VERSION ""

NS_ :

BS_:

BU_: XXX

BO_ 85 CID_SHPRSN: 8 XXX
 SG_ sig_mstjnl : 40|1@1+ (1,0) [0|1] "" XXX
 SG_ sig_nvbqlo : 56|8@1+ (1,0) [0|255] "" XXX

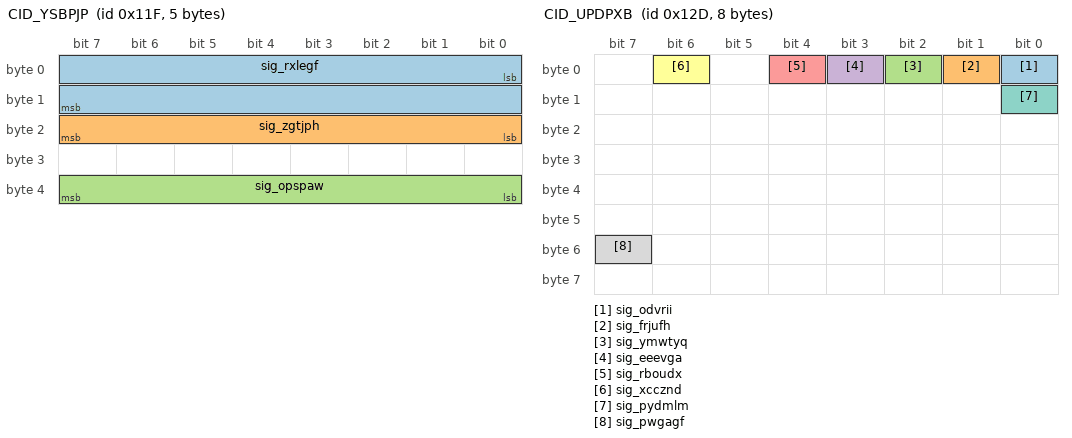
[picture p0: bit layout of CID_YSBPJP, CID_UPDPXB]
BO_ 287 CID_YSBPJP: 5 XXX
 SG_ sig_rxlegf : 0|16@1- (0.1,0) [-450|450] "" XXX
 SG_ sig_zgtjph : 16|8@1+ (4,0) [0|1020] "" XXX
 SG_ sig_opspaw : 32|8@1+ (1,0) [0|255] "" XXX

BO_ 289 CID_MHUZFI: 8 XXX
 SG_ sig_wpzvav : 0|12@1+ (1,0) [0|255] "" XXX

BO_ 301 CID_UPDPXB: 8 XXX
 SG_ sig_odvrii : 0|1@0+ (1,0) [0|1] "" XXX
 SG_ sig_frjufh : 1|1@0+ (1,0) [0|1] "" XXX
 SG_ sig_ymwtyq : 2|1@0+ (1,0) [0|1] "" XXX
 SG_ sig_eeevga : 3|1@0+ (1,0) [0|1] "" XXX
 SG_ sig_rboudx : 4|1@0+ (1,0) [0|1] "" XXX
 SG_ sig_xccznd : 6|1@0+ (1,0) [0|1] "" XXX
 SG_ sig_pydmlm : 8|1@0+ (1,0) [0|1] "" XXX
 SG_ sig_pwgagf : 55|1@0+ (1,0) [0|1] "" XXX

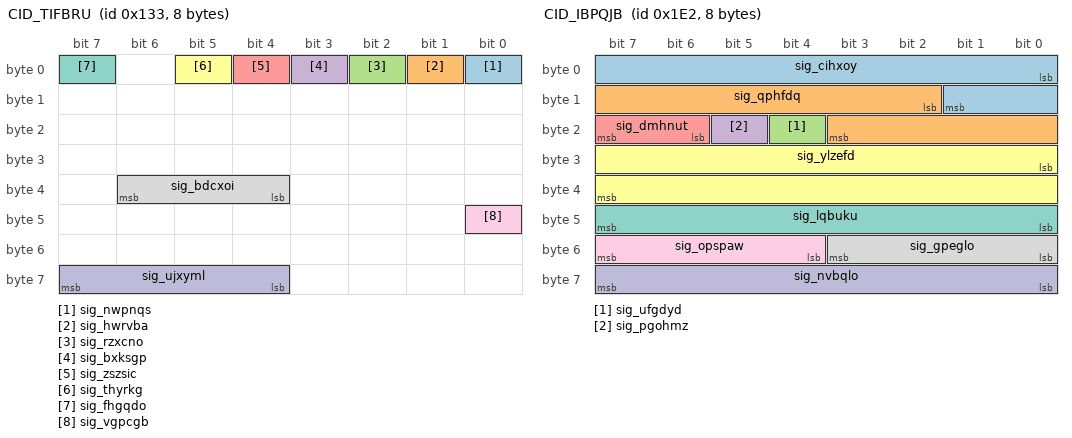
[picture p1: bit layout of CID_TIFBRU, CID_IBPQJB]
BO_ 307 CID_TIFBRU: 8 XXX
 SG_ sig_nwpnqs : 0|1@0+ (1,0) [0|1] "" XXX
 SG_ sig_hwrvba : 1|1@1+ (1,0) [0|1] "" XXX
 SG_ sig_rzxcno : 2|1@1+ (1,0) [0|1] "" XXX
 SG_ sig_bxksgp : 3|1@1+ (1,0) [0|1] "" XXX
 SG_ sig_zszsic : 4|1@0+ (1,0) [0|1] "" XXX
 SG_ sig_thyrkg : 5|1@0+ (1,0) [0|1] "" XXX
 SG_ sig_fhgqdo : 7|1@0+ (1,0) [0|1] "" XXX
 SG_ sig_bdcxoi : 36|3@1+ (1,0) [0|7] "" XXX
 SG_ sig_vgpcgb : 40|1@0+ (1,0) [0|1] "" XXX
 SG_ sig_ujxyml : 63|4@0+ (1,0) [0|15] "" XXX

BO_ 482 CID_IBPQJB: 8 XXX
 SG_ sig_cihxoy : 0|10@1- (0.01,0) [0|5] "" XXX
 SG_ sig_qphfdq : 10|10@1- (0.01,0) [-5|0] "" XXX
 SG_ sig_ufgdyd : 20|1@0+ (1,0) [0|1] "" XXX
 SG_ sig_pgohmz : 21|1@0+ (1,0) [0|1] "" XXX
 SG_ sig_dmhnut : 22|2@1+ (1,0) [0|1] "" XXX
 SG_ sig_ylzefd : 24|16@1- (0.1,0) [-780|779.9] "" XXX
 SG_ sig_lqbuku : 47|8@0+ (1,0) [0|255] "" XXX
 SG_ sig_gpeglo : 48|4@1+ (1,0) [0|15] "" XXX
 SG_ sig_opspaw : 52|4@1+ (1,0) [0|15] "" XXX
 SG_ sig_nvbqlo : 56|8@1+ (1,0) [0|255] "" XXX

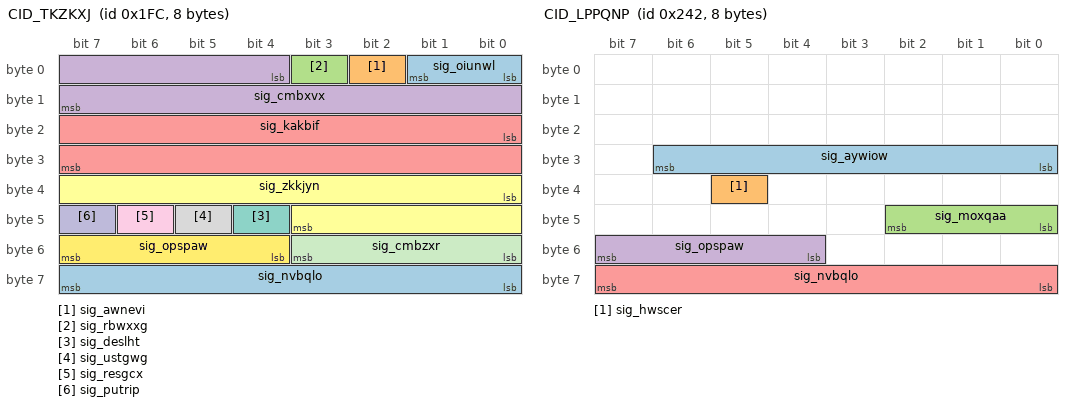
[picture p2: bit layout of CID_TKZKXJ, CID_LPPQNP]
BO_ 508 CID_TKZKXJ: 8 XXX
 SG_ sig_oiunwl : 0|2@1+ (1,0) [0|1] "" XXX
 SG_ sig_awnevi : 2|1@1+ (1,0) [0|1] "" XXX
 SG_ sig_rbwxxg : 3|1@0+ (1,0) [0|1] "" XXX
 SG_ sig_cmbxvx : 4|12@1- (1,0) [-2048|2047] "" XXX
 SG_ sig_kakbif : 16|16@1- (0.1,0) [-780|779.9] "Deg" XXX
 SG_ sig_zkkjyn : 32|12@1- (0.01,0) [0|63] "" XXX
 SG_ sig_deslht : 44|1@0+ (1,0) [0|1] "" XXX
 SG_ sig_ustgwg : 45|1@1+ (1,0) [0|255] "" XXX
 SG_ sig_resgcx : 46|1@1+ (1,0) [0|1] "" XXX
 SG_ sig_putrip : 47|1@0+ (1,0) [0|3] "" XXX
 SG_ sig_cmbzxr : 48|4@1+ (1,0) [0|15] "" XXX
 SG_ sig_opspaw : 52|4@1+ (1,0) [0|15] "" XXX
 SG_ sig_nvbqlo : 56|8@1+ (1,0) [0|255] "" XXX

BO_ 578 CID_LPPQNP: 8 XXX
 SG_ sig_aywiow : 30|7@0+ (1,0) [0|127] "" XXX
 SG_ sig_hwscer : 37|1@0+ (1,0) [0|1] "" XXX
 SG_ sig_moxqaa : 40|3@1+ (1,0) [0|7] "" XXX
 SG_ sig_opspaw : 55|4@0+ (1,0) [0|15] "" XXX
 SG_ sig_nvbqlo : 56|8@1+ (1,0) [0|255] "" XXX

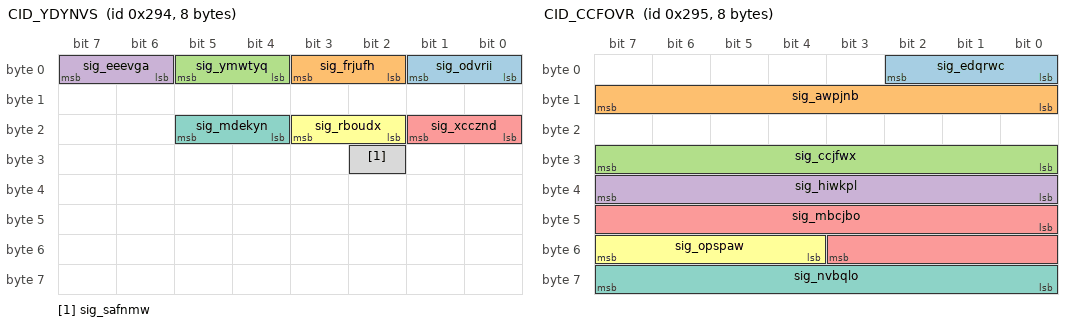
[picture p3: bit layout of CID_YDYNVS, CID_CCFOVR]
BO_ 660 CID_YDYNVS: 8 XXX
 SG_ sig_odvrii : 1|2@0+ (1,0) [0|3] "" XXX
 SG_ sig_frjufh : 3|2@0+ (1,0) [0|3] "" XXX
 SG_ sig_ymwtyq : 5|2@0+ (1,0) [0|3] "" XXX
 SG_ sig_eeevga : 7|2@0+ (1,0) [0|3] "" XXX
 SG_ sig_xccznd : 17|2@0+ (1,0) [0|3] "" XXX
 SG_ sig_rboudx : 19|2@0+ (1,0) [0|3] "" XXX
 SG_ sig_mdekyn : 21|2@0+ (1,0) [0|3] "" XXX
 SG_ sig_safnmw : 26|1@0+ (1,0) [0|1] "" XXX

BO_ 661 CID_CCFOVR: 8 XXX
 SG_ sig_edqrwc : 2|3@0+ (1,0) [0|7] "" XXX
 SG_ sig_awpjnb : 15|8@0+ (1,0) [0|255] "" XXX
 SG_ sig_ccjfwx : 31|8@0+ (1,0) [0|255] "" XXX
 SG_ sig_hiwkpl : 32|8@1+ (1,0) [0|255] "" XXX
 SG_ sig_mbcjbo : 40|12@1+ (1,0) [0|255] "" XXX
 SG_ sig_opspaw : 52|4@1+ (1,0) [0|15] "" XXX
 SG_ sig_nvbqlo : 63|8@0+ (1,0) [0|255] "" XXX

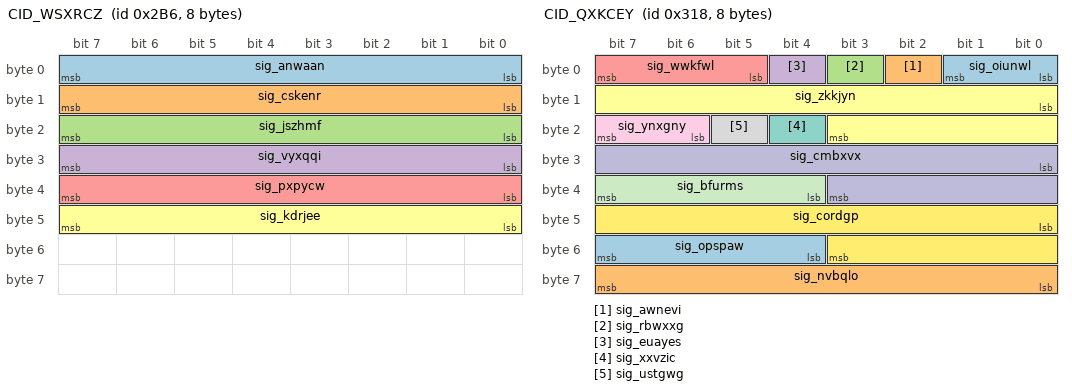
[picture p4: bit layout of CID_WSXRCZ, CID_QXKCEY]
BO_ 694 CID_WSXRCZ: 8 XXX
 SG_ sig_anwaan : 7|8@0+ (1,0) [0|255] "" XXX
 SG_ sig_cskenr : 15|8@0+ (1,0) [0|255] "" XXX
 SG_ sig_jszhmf : 23|8@0+ (1,0) [0|255] "" XXX
 SG_ sig_vyxqqi : 31|8@0+ (1,0) [0|255] "" XXX
 SG_ sig_pxpycw : 39|8@0+ (1,0) [0|255] "" XXX
 SG_ sig_kdrjee : 47|8@0+ (1,0) [0|255] "" XXX

BO_ 790 CID_KSSZPX: 8 XXX
 SG_ sig_ufqdkf : 3|4@0+ (1,0) [0|1] "" XXX
 SG_ sig_ealdik : 4|2@1+ (1,0) [0|3] "" XXX
 SG_ sig_iaiijy : 6|2@1+ (1,0) [0|3] "" XXX
 SG_ sig_beswdz : 8|2@1+ (1,0) [0|3] "" XXX
 SG_ sig_vrbsno : 10|1@1+ (1,0) [0|1] "" XXX
 SG_ sig_sihiqy : 11|4@1+ (1,0) [0|1] "" XXX
 SG_ sig_nokjrt : 15|1@0+ (1,0) [0|1] "" XXX
 SG_ sig_ylzefd : 16|11@1- (1,0) [-1024|1023] "" XXX
 SG_ sig_ufgdyd : 27|1@1+ (1,0) [0|1] "" XXX
 SG_ sig_pgohmz : 28|1@1+ (1,0) [0|3] "" XXX
 SG_ sig_wnoeiz : 29|1@0+ (1,0) [0|1] "" XXX
 SG_ sig_vikvqq : 30|1@0+ (1,0) [0|1] "" XXX
 SG_ sig_ddafoj : 31|1@0+ (1,0) [0|1] "" XXX
 SG_ sig_oxvdeb : 32|2@1+ (1,0) [0|3] "" XXX
 SG_ sig_cnyppa : 34|2@1+ (1,0) [0|3] "" XXX
 SG_ sig_ljmqjj : 36|4@1+ (1,0) [0|3] "" XXX
 SG_ sig_fbznym : 40|8@1+ (5,-5) [-5|1270] "" XXX
 SG_ sig_jzpfef : 49|2@0+ (1,0) [0|3] "" XXX
 SG_ sig_cqhiyo : 51|2@0+ (1,0) [0|3] "" XXX
 SG_ sig_opspaw : 52|4@1+ (1,0) [0|15] "" XXX
 SG_ sig_nvbqlo : 56|8@1+ (1,0) [0|15] "" XXX

BO_ 792 CID_QXKCEY: 8 XXX
 SG_ sig_oiunwl : 0|2@1+ (1,0) [0|1] "" XXX
 SG_ sig_awnevi : 2|1@1+ (1,0) [0|1] "" XXX
 SG_ sig_rbwxxg : 3|1@1+ (1,0) [0|1] "" XXX
 SG_ sig_euayes : 4|1@1+ (1,0) [0|1] "" XXX
 SG_ sig_wwkfwl : 5|3@1+ (1,0) [0|1] "" XXX
 SG_ sig_zkkjyn : 8|12@1- (1,0) [-2048|2047] "" XXX
 SG_ sig_xxvzic : 20|1@1+ (1,0) [0|1] "" XXX
 SG_ sig_ustgwg : 21|1@1+ (1,0) [0|1] "" XXX
 SG_ sig_ynxgny : 22|2@1+ (1,0) [0|15] "" XXX
 SG_ sig_cmbxvx : 24|12@1- (1,0) [-2048|2047] "" XXX
 SG_ sig_bfurms : 36|4@1+ (1,0) [0|15] "" XXX
 SG_ sig_cordgp : 40|12@1+ (1,0) [0|4095] "" XXX
 SG_ sig_opspaw : 52|4@1+ (1,0) [0|15] "" XXX
 SG_ sig_nvbqlo : 56|8@1+ (1,0) [0|255] "" XXX

BO_ 813 CID_FPKZLG: 8 XXX
 SG_ sig_zvgikm : 0|9@1+ (0.5,0) [0|255.5] "" XXX
 SG_ sig_crgucz : 9|1@1+ (1,0) [0|1] "" XXX
 SG_ sig_lhgjap : 10|3@1+ (1,0) [0|7] "" XXX
 SG_ sig_jkobrm : 13|3@1+ (1,0) [0|7] "" XXX
 SG_ sig_efmxob : 16|1@1+ (1,0) [0|1] "" XXX
 SG_ sig_dqgvyd : 17|1@1+ (1,0) [0|1] "" XXX
 SG_ sig_rbwxxg : 18|1@1+ (1,0) [0|1] "" XXX
 SG_ sig_eudesy : 19|3@1+ (1,0) [0|1] "" XXX
 SG_ sig_dmtguj : 22|1@0+ (1,0) [0|1] "" XXX
 SG_ sig_fpggzb : 23|1@0+ (1,0) [0|1] "" XXX
 SG_ sig_beswdz : 24|1@1+ (1,0) [0|1] "" XXX
 SG_ sig_teslqp : 25|7@1+ (1,0) [0|127] "" XXX
 SG_ sig_gxwmml : 32|4@1+ (1,0) [0|15] "" XXX
 SG_ sig_zkavbg : 36|12@1+ (1,0) [0|4095] "" XXX
 SG_ sig_opspaw : 48|4@1+ (1,0) [0|15] "" XXX
 SG_ sig_dseuan : 55|4@0+ (1,0) [0|15] "" XXX
 SG_ sig_nvbqlo : 56|8@1+ (1,0) [0|255] "" XXX

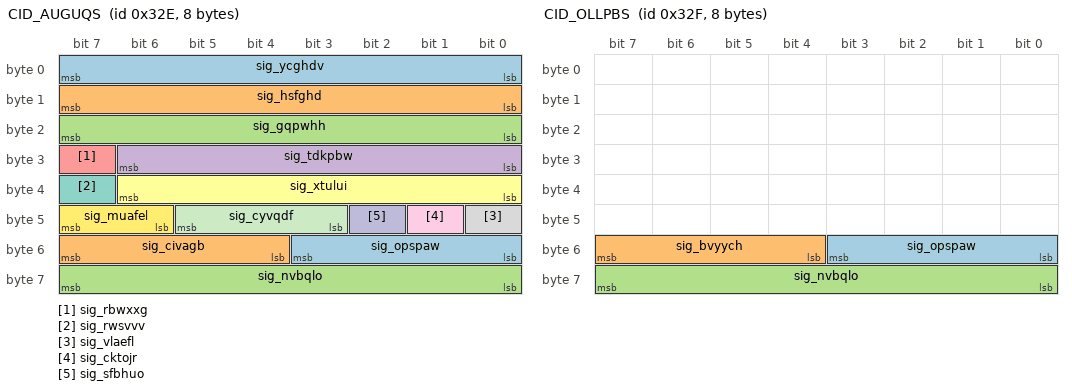
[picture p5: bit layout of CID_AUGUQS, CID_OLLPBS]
BO_ 814 CID_AUGUQS: 8 XXX
 SG_ sig_ycghdv : 0|8@1+ (0.05,-5) [-100|155] "" XXX
 SG_ sig_hsfghd : 8|8@1+ (0.05,-5) [0|1.26] "" XXX
 SG_ sig_gqpwhh : 16|8@1+ (0.05,-5) [0|1.26] "" XXX
 SG_ sig_tdkpbw : 24|7@1+ (0.2,0) [0|12.7] "" XXX
 SG_ sig_rbwxxg : 31|1@0+ (1,0) [0|1] "" XXX
 SG_ sig_xtului : 32|7@1+ (0.2,-16) [0|12.7] "" XXX
 SG_ sig_rwsvvv : 39|1@0+ (1,0) [0|1] "" XXX
 SG_ sig_vlaefl : 40|1@0+ (1,0) [0|1] "" XXX
 SG_ sig_cktojr : 41|1@0+ (1,0) [0|1] "" XXX
 SG_ sig_sfbhuo : 42|1@1+ (1,0) [0|3] "" XXX
 SG_ sig_cyvqdf : 45|3@0+ (1,0) [0|1] "" XXX
 SG_ sig_muafel : 46|2@1+ (1,0) [0|3] "" XXX
 SG_ sig_opspaw : 48|4@1+ (1,0) [0|15] "" XXX
 SG_ sig_civagb : 55|4@0+ (1,0) [0|15] "" XXX
 SG_ sig_nvbqlo : 56|8@1+ (1,0) [0|255] "" XXX

BO_ 815 CID_OLLPBS: 8 XXX
 SG_ sig_opspaw : 48|4@1+ (1,0) [0|15] "" XXX
 SG_ sig_bvyych : 55|4@0+ (1,0) [0|15] "" XXX
 SG_ sig_nvbqlo : 56|8@1+ (1,0) [0|255] "" XXX

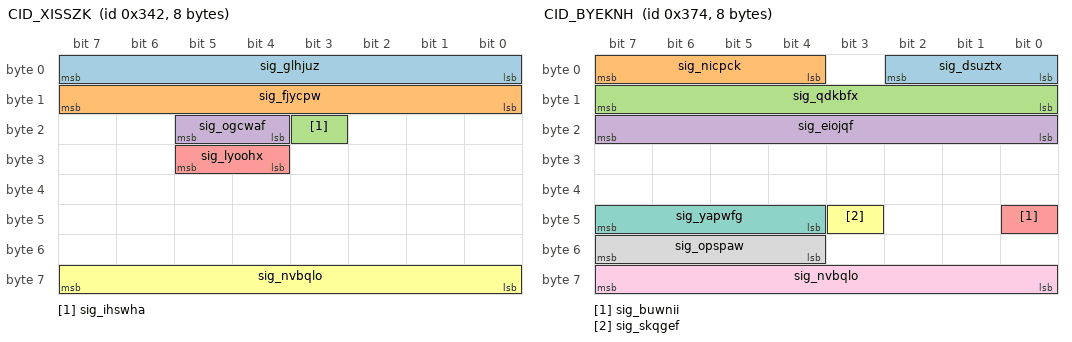
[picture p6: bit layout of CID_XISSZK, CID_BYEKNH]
BO_ 834 CID_XISSZK: 8 XXX
 SG_ sig_glhjuz : 0|8@1+ (0.01,0) [0|2.55] "" XXX
 SG_ sig_fjycpw : 8|8@1+ (0.01,0) [0|2.55] "" XXX
 SG_ sig_ihswha : 19|1@1+ (1,0) [0|1] "" XXX
 SG_ sig_ogcwaf : 20|2@1+ (1,0) [0|255] "" XXX
 SG_ sig_lyoohx : 28|2@1+ (1,0) [0|1] "" XXX
 SG_ sig_nvbqlo : 56|8@1+ (1,0) [0|255] "" XXX

 BO_ 884 CID_BYEKNH: 8 MRR
 SG_ sig_dsuztx : 2|3@0+ (1,0) [0|3] "" MRR
 SG_ sig_nicpck : 7|4@0+ (1,0) [0|15] "" MRR
 SG_ sig_qdkbfx : 15|8@0+ (0.1,-12) [0|255] "" MRR
 SG_ sig_eiojqf : 23|8@0+ (1,-100) [0|255] "" MRR
 SG_ sig_buwnii : 40|1@0+ (1,0) [0|3] "" MRR
 SG_ sig_skqgef : 43|1@0+ (1,0) [0|1] "" XXX
 SG_ sig_yapwfg : 44|4@1+ (1,0) [0|15] "" XXX
 SG_ sig_opspaw : 52|4@1+ (1,0) [0|15] "" MRR
 SG_ sig_nvbqlo : 56|8@1+ (1,0) [0|255] "" MRR

BO_ 944 CID_NYYFKY: 8 XXX
 SG_ sig_xgpfiw : 1|2@0+ (1,0) [0|3] "" XXX
 SG_ sig_drlsvk : 2|1@0+ (1,0) [0|1] "" XXX
 SG_ sig_dmlqjp : 4|2@0+ (1,0) [0|3] "" XXX
 SG_ sig_mvbupz : 5|1@0+ (1,0) [0|1] "" XXX
 SG_ sig_zjkcdw : 6|1@0+ (1,0) [0|1] "" XXX
 SG_ sig_hjdzse : 7|1@0+ (1,0) [0|1] "" XXX
 SG_ sig_drenga : 8|1@0+ (1,0) [0|1] "" XXX
 SG_ sig_fucela : 11|3@0+ (1,0) [0|7] "" XXX
 SG_ sig_rhzrzx : 12|1@0+ (1,0) [0|1] "" XXX
 SG_ sig_imwzat : 14|2@0+ (1,0) [0|3] "" XXX
 SG_ sig_edcaux : 15|1@0+ (1,0) [0|1] "" XXX
 SG_ sig_kfzssy : 16|1@0+ (1,0) [0|1] "" XXX
 SG_ sig_yicpfo : 18|2@0+ (1,0) [0|3] "" XXX
 SG_ sig_aohsrd : 19|1@0+ (1,0) [0|1] "" XXX
 SG_ sig_vztlec : 23|4@0+ (1,0) [0|15] "" XXX
 SG_ sig_euzxdb : 24|28@1+ (1,0) [0|268435455] "" XXX
 SG_ sig_opspaw : 52|4@1+ (1,0) [0|15] "" XXX
 SG_ sig_nvbqlo : 56|8@1+ (1,0) [0|255] "" XXX

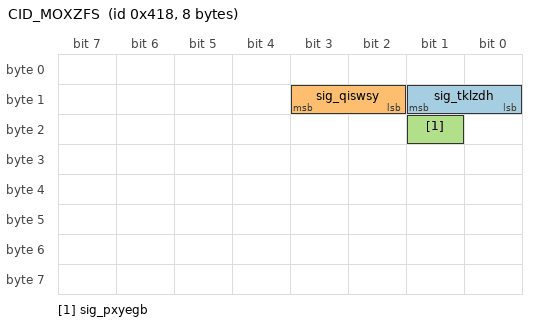
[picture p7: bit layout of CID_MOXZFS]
BO_ 1048 CID_MOXZFS: 8 XXX
 SG_ sig_tklzdh : 9|2@0+ (1,0) [0|1] "" XXX
 SG_ sig_qiswsy : 11|2@0+ (1,0) [0|1] "" XXX
 SG_ sig_pxyegb : 17|1@0+ (1,0) [0|1] "" XXX

VAL_ 578 sig_moxqaa 4 "D" 2 "R" 3 "N" 1 "P";
VAL_ 790 sig_ufqdkf 11 "AutoFullBeamActive" 2 "AutoFullBeamInactive";
VAL_ 790 sig_ealdik 0 "GRAY" 1 "GREEN" 2 "YELLOW" 3 "RED";
VAL_ 790 sig_iaiijy 3 "ALARM_AND_LKA" 2 "LKA" 1 "ALARM" 0 "DISABLE";
VAL_ 790 sig_cnyppa 0 "GRAY" 1 "GREEN" 2 "YELLOW" 3 "RED";
VAL_ 790 sig_jzpfef 0 "VIBRATION" 1 "AUDIO" 2 "AUDIO_AND_VIBRATION";
VAL_ 792 sig_oiunwl 0 "NotReady" 1 "Ready" 2 "Active" 3 "TemporaryFail";
VAL_ 813 sig_lhgjap 4 "4BAR" 3 "3BAR" 2 "2BAR" 1 "1BAR";
VAL_ 813 sig_eudesy 0 "OFF" 2 "ACC_ON" 3 "ACC_ACTIVE" 5 "FORCE_ACCEL" 7 "ERROR";
VAL_ 813 sig_teslqp 36 "ACC_ERROR" 22 "OVERRIDE" 12 "ENGAGE" 8 "DISENGAGE" 20 "ACC_ON" 32 "ACC_OFF" 48 "CHECK_GEAR_D" 16 "FORCE_ACCEL" 0 "NONE";
VAL_ 814 sig_cyvqdf 0 "Off" 1 "Passive" 2 "StandBy" 3 "ActiveControl" 4 "BrakeOnly" 5 "Override" 6 "Standstill" 7 "Failure";
VAL_ 814 sig_muafel 0 "Softoff" 1 "Fastoff" 2 "Immediateoff" 3 "Initial";
VAL_ 834 sig_ogcwaf 2 "SPORT" 1 "ECO" 0 "SNOW";
VAL_ 834 sig_lyoohx 3 "HEV" 2 "FORCE_EV" 1 "EV";
VAL_ 944 sig_dmlqjp 0 "NOTPRESSED" 1 "DOWN_SETSPEED" 3 "UP_RESETSPEED";
